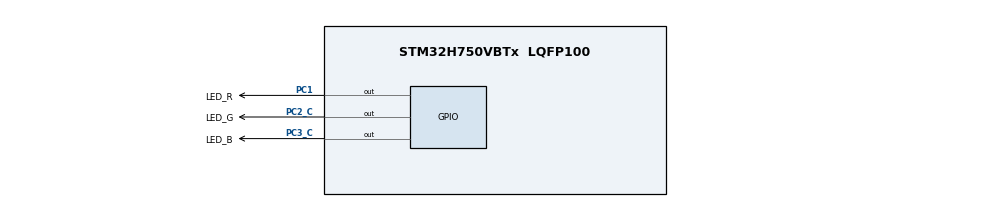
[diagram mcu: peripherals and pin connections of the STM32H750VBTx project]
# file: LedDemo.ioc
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Mcu.Family=STM32H7
Mcu.Name=STM32H750VBTx
Mcu.Package=LQFP100
NVIC.PriorityGroup=NVIC_PRIORITYGROUP_4
PC1.GPIO_Label=LED_R
PC1.GPIO_ModeDefaultOutputPP=GPIO_MODE_OUTPUT_PP
PC1.GPIO_PuPd=GPIO_PULLUP
PC1.GPIO_Speed=GPIO_SPEED_FREQ_VERY_HIGH
PC1.PinState=GPIO_PIN_SET
PC1.Signal=GPIO_Output
PC14-OSC32_IN\ (OSC32_IN).Mode=LSE-External-Oscillator
PC14-OSC32_IN\ (OSC32_IN).Signal=RCC_OSC32_IN
PC15-OSC32_OUT\ (OSC32_OUT).Mode=LSE-External-Oscillator
PC15-OSC32_OUT\ (OSC32_OUT).Signal=RCC_OSC32_OUT
PC2_C.GPIO_Label=LED_G
PC2_C.GPIO_PuPd=GPIO_PULLUP
PC2_C.GPIO_Speed=GPIO_SPEED_FREQ_VERY_HIGH
PC2_C.PinState=GPIO_PIN_SET
PC2_C.Signal=GPIO_Output
PC3_C.GPIO_Label=LED_B
PC3_C.GPIO_PuPd=GPIO_PULLUP
PC3_C.GPIO_Speed=GPIO_SPEED_FREQ_VERY_HIGH
PC3_C.PinState=GPIO_PIN_SET
PC3_C.Signal=GPIO_Output
PH0-OSC_IN\ (PH0).Mode=HSE-External-Oscillator
PH0-OSC_IN\ (PH0).Signal=RCC_OSC_IN
PH1-OSC_OUT\ (PH1).Mode=HSE-External-Oscillator
PH1-OSC_OUT\ (PH1).Signal=RCC_OSC_OUT
ProjectManager.HeapSize=0x200
ProjectManager.StackSize=0x400
ProjectManager.TargetToolchain=MDK-ARM V5.32
RCC.ADCFreq_Value=129000000
RCC.APB1Freq_Value=64000000
RCC.APB2Freq_Value=64000000
RCC.APB3Freq_Value=64000000
RCC.APB4Freq_Value=64000000
RCC.CortexFreq_Value=64000000
RCC.HCLKFreq_Value=64000000
RCC.SYSCLKFreq_VALUE=64000000
RCC.USBFreq_Value=129000000
board=custom

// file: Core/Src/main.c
/* USER CODE BEGIN Header */
/**
  ******************************************************************************
  * @file           : main.c
  * @brief          : Main program body
  ******************************************************************************
  * @attention
  *
  * Copyright (c) 2023 STMicroelectronics.
  * All rights reserved.
  *
  * This software is licensed under terms that can be found in the LICENSE file
  * in the root directory of this software component.
  * If no LICENSE file comes with this software, it is provided AS-IS.
  *
  ******************************************************************************
  */
/* USER CODE END Header */
#include "main.h"
#include "gpio.h"

/* USER CODE BEGIN Includes */
#include "ledDev.h"
#include "ramtest.h"
#include <string.h>
/* USER CODE END Includes */

void SystemClock_Config(void);

int main(void)
{

  /* MCU Configuration--------------------------------------------------------*/

  /* Reset of all peripherals, Initializes the Flash interface and the Systick. */
  HAL_Init();

  /* Configure the system clock */
  SystemClock_Config();

  /* Initialize all configured peripherals */
  MX_GPIO_Init();
  /* USER CODE BEGIN 2 */
	usedata1();
  /* USER CODE END 2 */

  /* Infinite loop */
  while (1)
  {

    /* USER CODE BEGIN 3 */
//    HAL_GPIO_WritePin(LED_B_GPIO_Port, LED_B_Pin, LED_OFF);
//    HAL_GPIO_WritePin(LED_R_GPIO_Port, LED_R_Pin, LED_ON);
//    HAL_Delay(1000);
//    HAL_GPIO_WritePin(LED_R_GPIO_Port, LED_R_Pin, LED_OFF);
//    HAL_GPIO_WritePin(LED_G_GPIO_Port, LED_G_Pin, LED_ON);
//    HAL_Delay(1000);
//    HAL_GPIO_WritePin(LED_G_GPIO_Port, LED_G_Pin, LED_OFF);
//    HAL_GPIO_WritePin(LED_B_GPIO_Port, LED_B_Pin, LED_ON);
    HAL_Delay(1000);
  }
  /* USER CODE END 3 */
}

void SystemClock_Config(void)
{
  RCC_OscInitTypeDef RCC_OscInitStruct = {0};
  RCC_ClkInitTypeDef RCC_ClkInitStruct = {0};

  /** Supply configuration update enable
  */
  HAL_PWREx_ConfigSupply(PWR_LDO_SUPPLY);

  /** Configure the main internal regulator output voltage
  */
  __HAL_PWR_VOLTAGESCALING_CONFIG(PWR_REGULATOR_VOLTAGE_SCALE3);

  while(!__HAL_PWR_GET_FLAG(PWR_FLAG_VOSRDY)) {}

  /** Initializes the RCC Oscillators according to the specified parameters
  * in the RCC_OscInitTypeDef structure.
  */
  RCC_OscInitStruct.OscillatorType = RCC_OSCILLATORTYPE_HSI;
  RCC_OscInitStruct.HSIState = RCC_HSI_DIV1;
  RCC_OscInitStruct.HSICalibrationValue = RCC_HSICALIBRATION_DEFAULT;
  RCC_OscInitStruct.PLL.PLLState = RCC_PLL_NONE;
  if (HAL_RCC_OscConfig(&RCC_OscInitStruct) != HAL_OK)
  {
    Error_Handler();
  }

  /** Initializes the CPU, AHB and APB buses clocks
  */
  RCC_ClkInitStruct.ClockType = RCC_CLOCKTYPE_HCLK|RCC_CLOCKTYPE_SYSCLK
                              |RCC_CLOCKTYPE_PCLK1|RCC_CLOCKTYPE_PCLK2
                              |RCC_CLOCKTYPE_D3PCLK1|RCC_CLOCKTYPE_D1PCLK1;
  RCC_ClkInitStruct.SYSCLKSource = RCC_SYSCLKSOURCE_HSI;
  RCC_ClkInitStruct.SYSCLKDivider = RCC_SYSCLK_DIV1;
  RCC_ClkInitStruct.AHBCLKDivider = RCC_HCLK_DIV1;
  RCC_ClkInitStruct.APB3CLKDivider = RCC_APB3_DIV1;
  RCC_ClkInitStruct.APB1CLKDivider = RCC_APB1_DIV1;
  RCC_ClkInitStruct.APB2CLKDivider = RCC_APB2_DIV1;
  RCC_ClkInitStruct.APB4CLKDivider = RCC_APB4_DIV1;

  if (HAL_RCC_ClockConfig(&RCC_ClkInitStruct, FLASH_LATENCY_1) != HAL_OK)
  {
    Error_Handler();
  }
}

void Error_Handler(void)
{
  __disable_irq();
  while (1)
  {
  }
}
